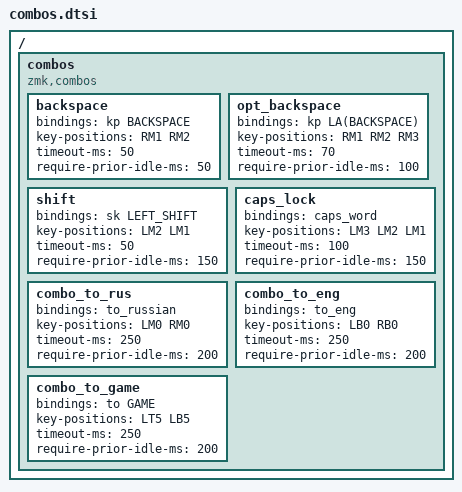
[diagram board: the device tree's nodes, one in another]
/*                                      42 KEY MATRIX / LAYOUT MAPPING

  ╭────────────────────────┬────────────────────────╮ ╭─────────────────────────┬─────────────────────────╮
  │  0   1   2   3   4   5 │  6   7   8   9  10  11 │ │ LT5 LT4 LT3 LT2 LT1 LT0 │ RT0 RT1 RT2 RT3 RT4 RT5 │
  │ 12  13  14  15  16  17 │ 18  19  20  21  22  23 │ │ LM5 LM4 LM3 LM2 LM1 LM0 │ RM0 RM1 RM2 RM3 RM4 RM5 │
  │ 24  25  26  27  28  29 │ 30  31  32  33  34  35 │ │ LB5 LB4 LB3 LB2 LB1 LB0 │ RB0 RB1 RB2 RB3 RB4 RB5 │
  ╰───────────╮ 36  37  38 │ 39  40  41 ╭───────────╯ ╰───────────╮ LH2 LH1 LH0 │ RH0 RH1 RH2 ╭───────────╯
              ╰────────────┴────────────╯                         ╰─────────────┴─────────────╯             */


/ {

    combos {
        compatible = "zmk,combos";

        backspace {
            bindings = <&kp BACKSPACE>;
            key-positions = <RM1 RM2>;
            timeout-ms = <50>;
            require-prior-idle-ms = <50>;
        };

        opt_backspace {
            bindings = <&kp LA(BACKSPACE)>;
            key-positions = <RM1 RM2 RM3>;
            timeout-ms = <70>;
            require-prior-idle-ms = <100>;
        };

        shift {
            bindings = <&sk LEFT_SHIFT>;
            key-positions = <LM2 LM1>;
            timeout-ms = <50>;
            require-prior-idle-ms = <150>;
        };

        caps_lock {
            bindings = <&caps_word>;
            key-positions = <LM3 LM2 LM1>;
            timeout-ms = <100>;
            require-prior-idle-ms = <150>;
        };

        combo_to_rus {
            bindings = <&to_russian>;
            key-positions = <LM0 RM0>;
            timeout-ms = <250>;
            require-prior-idle-ms = <200>;
        };

        combo_to_eng {
            bindings = <&to_eng>;
            key-positions = <LB0 RB0>;
            timeout-ms = <250>;
            require-prior-idle-ms = <200>;
        };

        combo_to_game {
            bindings = <&to GAME>;
            key-positions = <LT5 LB5>;
            timeout-ms = <250>;
            require-prior-idle-ms = <200>;
        };

    };
};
